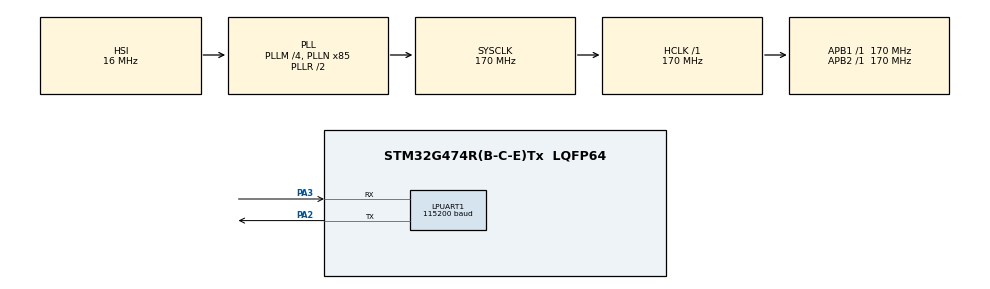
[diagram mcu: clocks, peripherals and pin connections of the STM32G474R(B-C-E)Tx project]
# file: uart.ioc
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Dma.LPUART1_RX.1.Direction=DMA_PERIPH_TO_MEMORY
Dma.LPUART1_RX.1.EventEnable=DISABLE
Dma.LPUART1_RX.1.Instance=DMA1_Channel2
Dma.LPUART1_RX.1.MemDataAlignment=DMA_MDATAALIGN_BYTE
Dma.LPUART1_RX.1.MemInc=DMA_MINC_ENABLE
Dma.LPUART1_RX.1.Mode=DMA_NORMAL
Dma.LPUART1_RX.1.PeriphDataAlignment=DMA_PDATAALIGN_BYTE
Dma.LPUART1_RX.1.PeriphInc=DMA_PINC_DISABLE
Dma.LPUART1_RX.1.Polarity=HAL_DMAMUX_REQ_GEN_RISING
Dma.LPUART1_RX.1.Priority=DMA_PRIORITY_LOW
Dma.LPUART1_RX.1.RequestNumber=1
Dma.LPUART1_RX.1.SignalID=NONE
Dma.LPUART1_RX.1.SyncEnable=DISABLE
Dma.LPUART1_RX.1.SyncPolarity=HAL_DMAMUX_SYNC_NO_EVENT
Dma.LPUART1_RX.1.SyncRequestNumber=1
Dma.LPUART1_RX.1.SyncSignalID=NONE
Dma.LPUART1_TX.0.Direction=DMA_MEMORY_TO_PERIPH
Dma.LPUART1_TX.0.EventEnable=DISABLE
Dma.LPUART1_TX.0.Instance=DMA1_Channel1
Dma.LPUART1_TX.0.MemDataAlignment=DMA_MDATAALIGN_BYTE
Dma.LPUART1_TX.0.MemInc=DMA_MINC_ENABLE
Dma.LPUART1_TX.0.Mode=DMA_NORMAL
Dma.LPUART1_TX.0.PeriphDataAlignment=DMA_PDATAALIGN_BYTE
Dma.LPUART1_TX.0.PeriphInc=DMA_PINC_DISABLE
Dma.LPUART1_TX.0.Polarity=HAL_DMAMUX_REQ_GEN_RISING
Dma.LPUART1_TX.0.Priority=DMA_PRIORITY_LOW
Dma.LPUART1_TX.0.RequestNumber=1
Dma.LPUART1_TX.0.SignalID=NONE
Dma.LPUART1_TX.0.SyncEnable=DISABLE
Dma.LPUART1_TX.0.SyncPolarity=HAL_DMAMUX_SYNC_NO_EVENT
Dma.LPUART1_TX.0.SyncRequestNumber=1
Dma.LPUART1_TX.0.SyncSignalID=NONE
Dma.Request0=LPUART1_TX
Dma.Request1=LPUART1_RX
LPUART1.BaudRate=115200
Mcu.Family=STM32G4
Mcu.Name=STM32G474R(B-C-E)Tx
Mcu.Package=LQFP64
NVIC.DMA1_Channel1_IRQn=true\:0\:0\:false\:false\:true\:false\:true\:true
NVIC.DMA1_Channel2_IRQn=true\:0\:0\:false\:false\:true\:false\:true\:true
NVIC.LPUART1_IRQn=true\:1\:0\:true\:false\:true\:true\:true\:true
NVIC.PriorityGroup=NVIC_PRIORITYGROUP_4
PA13.Mode=Serial_Wire
PA13.Signal=SYS_JTMS-SWDIO
PA14.Mode=Serial_Wire
PA14.Signal=SYS_JTCK-SWCLK
PA2.Mode=Asynchronous
PA2.Signal=LPUART1_TX
PA3.Mode=Asynchronous
PA3.Signal=LPUART1_RX
PF0-OSC_IN.Mode=HSE-External-Oscillator
PF0-OSC_IN.Signal=RCC_OSC_IN
PF1-OSC_OUT.Mode=HSE-External-Oscillator
PF1-OSC_OUT.Signal=RCC_OSC_OUT
ProjectManager.HeapSize=0x200
ProjectManager.StackSize=0x400
ProjectManager.TargetToolchain=CMake
RCC.ADC12Freq_Value=170000000
RCC.ADC345Freq_Value=170000000
RCC.AHBFreq_Value=170000000
RCC.APB1Freq_Value=170000000
RCC.APB1TimFreq_Value=170000000
RCC.APB2Freq_Value=170000000
RCC.APB2TimFreq_Value=170000000
RCC.CortexFreq_Value=170000000
RCC.EXTERNAL_CLOCK_VALUE=12288000
RCC.HCLKFreq_Value=170000000
RCC.HSE_VALUE=24000000
RCC.HSI48_VALUE=48000000
RCC.HSI_VALUE=16000000
RCC.LSE_VALUE=32768
RCC.PLLM=RCC_PLLM_DIV4
RCC.PLLN=85
RCC.SYSCLKFreq_VALUE=170000000
RCC.SYSCLKSource=RCC_SYSCLKSOURCE_PLLCLK
RCC.USBFreq_Value=170000000
RCC.VCOOutputFreq_Value=340000000
VP_SYS_VS_DBSignals.Mode=DisableDeadBatterySignals
board=custom

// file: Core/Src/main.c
/* USER CODE BEGIN Header */
/**
  ******************************************************************************
  * @file           : main.c
  * @brief          : Main program body
  ******************************************************************************
  * @attention
  *
  * Copyright (c) 2026 STMicroelectronics.
  * All rights reserved.
  *
  * This software is licensed under terms that can be found in the LICENSE file
  * in the root directory of this software component.
  * If no LICENSE file comes with this software, it is provided AS-IS.
  *
  ******************************************************************************
  */
/* USER CODE END Header */
#include "main.h"

/* USER CODE BEGIN Includes */
#include <stdio.h>
#include <string.h>
/* USER CODE END Includes */

/* USER CODE BEGIN PD */
#define UART_RX_BUFFER_SIZE          128U

/* USER CODE END PD */

UART_HandleTypeDef hlpuart1;
DMA_HandleTypeDef hdma_lpuart1_tx;
DMA_HandleTypeDef hdma_lpuart1_rx;

/* USER CODE BEGIN PV */
uint8_t received_data[UART_RX_BUFFER_SIZE];
uint8_t transmit_data[UART_RX_BUFFER_SIZE];
volatile uint16_t transmit_length;
/* USER CODE END PV */

void SystemClock_Config(void);
static void MX_GPIO_Init(void);
static void MX_DMA_Init(void);
static void MX_LPUART1_UART_Init(void);

/* USER CODE BEGIN 0 */
static void UART_StartReceiveToIdleDMA(void)
{
  if (HAL_UARTEx_ReceiveToIdle_DMA(&hlpuart1,
                                   received_data,
                                   UART_RX_BUFFER_SIZE) == HAL_OK)
  {
    __HAL_DMA_DISABLE_IT(hlpuart1.hdmarx, DMA_IT_HT);
  }
}

void HAL_UARTEx_RxEventCallback(UART_HandleTypeDef *huart, uint16_t Size)
{
  if ((huart == &hlpuart1) && (Size > 0U))
  {
    transmit_length = (Size <= UART_RX_BUFFER_SIZE) ? Size : UART_RX_BUFFER_SIZE;
    memcpy(transmit_data, received_data, transmit_length);

    if (HAL_UART_Transmit_DMA(&hlpuart1,
                              transmit_data,
                              transmit_length) != HAL_OK)
    {
      UART_StartReceiveToIdleDMA();
    }
  }
}

void HAL_UART_TxCpltCallback(UART_HandleTypeDef *huart)
{
  if (huart == &hlpuart1)
  {
    UART_StartReceiveToIdleDMA();
  }
}
/* USER CODE END 0 */

int main(void)
{

  /* MCU Configuration--------------------------------------------------------*/

  /* Reset of all peripherals, Initializes the Flash interface and the Systick. */
  HAL_Init();

  /* Configure the system clock */
  SystemClock_Config();

  /* Initialize all configured peripherals */
  MX_GPIO_Init();
  MX_DMA_Init();
  MX_LPUART1_UART_Init();
  /* USER CODE BEGIN 2 */
  printf("\r\nUART Printf Example: retarget the C library printf function to the UART\r\n");
  printf("** Test finished successfully. **\r\n");

  UART_StartReceiveToIdleDMA();

  /* USER CODE END 2 */

  /* Infinite loop */
  while (1)
  {

    /* USER CODE BEGIN 3 */
      //HAL_UART_Receive(&hlpuart1, received_data, 2, HAL_MAX_DELAY);

  }
  /* USER CODE END 3 */
}

void SystemClock_Config(void)
{
  RCC_OscInitTypeDef RCC_OscInitStruct = {0};
  RCC_ClkInitTypeDef RCC_ClkInitStruct = {0};

  /** Configure the main internal regulator output voltage
  */
  HAL_PWREx_ControlVoltageScaling(PWR_REGULATOR_VOLTAGE_SCALE1_BOOST);

  /** Initializes the RCC Oscillators according to the specified parameters
  * in the RCC_OscInitTypeDef structure.
  */
  RCC_OscInitStruct.OscillatorType = RCC_OSCILLATORTYPE_HSI;
  RCC_OscInitStruct.HSIState = RCC_HSI_ON;
  RCC_OscInitStruct.HSICalibrationValue = RCC_HSICALIBRATION_DEFAULT;
  RCC_OscInitStruct.PLL.PLLState = RCC_PLL_ON;
  RCC_OscInitStruct.PLL.PLLSource = RCC_PLLSOURCE_HSI;
  RCC_OscInitStruct.PLL.PLLM = RCC_PLLM_DIV4;
  RCC_OscInitStruct.PLL.PLLN = 85;
  RCC_OscInitStruct.PLL.PLLP = RCC_PLLP_DIV2;
  RCC_OscInitStruct.PLL.PLLQ = RCC_PLLQ_DIV2;
  RCC_OscInitStruct.PLL.PLLR = RCC_PLLR_DIV2;
  if (HAL_RCC_OscConfig(&RCC_OscInitStruct) != HAL_OK)
  {
    Error_Handler();
  }

  /** Initializes the CPU, AHB and APB buses clocks
  */
  RCC_ClkInitStruct.ClockType = RCC_CLOCKTYPE_HCLK|RCC_CLOCKTYPE_SYSCLK
                              |RCC_CLOCKTYPE_PCLK1|RCC_CLOCKTYPE_PCLK2;
  RCC_ClkInitStruct.SYSCLKSource = RCC_SYSCLKSOURCE_PLLCLK;
  RCC_ClkInitStruct.AHBCLKDivider = RCC_SYSCLK_DIV1;
  RCC_ClkInitStruct.APB1CLKDivider = RCC_HCLK_DIV1;
  RCC_ClkInitStruct.APB2CLKDivider = RCC_HCLK_DIV1;

  if (HAL_RCC_ClockConfig(&RCC_ClkInitStruct, FLASH_LATENCY_4) != HAL_OK)
  {
    Error_Handler();
  }
}

static void MX_LPUART1_UART_Init(void)
{

  hlpuart1.Instance = LPUART1;
  hlpuart1.Init.BaudRate = 115200;
  hlpuart1.Init.WordLength = UART_WORDLENGTH_8B;
  hlpuart1.Init.StopBits = UART_STOPBITS_1;
  hlpuart1.Init.Parity = UART_PARITY_NONE;
  hlpuart1.Init.Mode = UART_MODE_TX_RX;
  hlpuart1.Init.HwFlowCtl = UART_HWCONTROL_NONE;
  hlpuart1.Init.OneBitSampling = UART_ONE_BIT_SAMPLE_DISABLE;
  hlpuart1.Init.ClockPrescaler = UART_PRESCALER_DIV1;
  hlpuart1.AdvancedInit.AdvFeatureInit = UART_ADVFEATURE_NO_INIT;
  if (HAL_UART_Init(&hlpuart1) != HAL_OK)
  {
    Error_Handler();
  }
  if (HAL_UARTEx_SetTxFifoThreshold(&hlpuart1, UART_TXFIFO_THRESHOLD_1_8) != HAL_OK)
  {
    Error_Handler();
  }
  if (HAL_UARTEx_SetRxFifoThreshold(&hlpuart1, UART_RXFIFO_THRESHOLD_1_8) != HAL_OK)
  {
    Error_Handler();
  }
  if (HAL_UARTEx_DisableFifoMode(&hlpuart1) != HAL_OK)
  {
    Error_Handler();
  }

}

static void MX_DMA_Init(void)
{

  /* DMA controller clock enable */
  __HAL_RCC_DMAMUX1_CLK_ENABLE();
  __HAL_RCC_DMA1_CLK_ENABLE();

  /* DMA interrupt init */
  /* DMA1_Channel1_IRQn interrupt configuration */
  HAL_NVIC_SetPriority(DMA1_Channel1_IRQn, 0, 0);
  HAL_NVIC_EnableIRQ(DMA1_Channel1_IRQn);
  /* DMA1_Channel2_IRQn interrupt configuration */
  HAL_NVIC_SetPriority(DMA1_Channel2_IRQn, 0, 0);
  HAL_NVIC_EnableIRQ(DMA1_Channel2_IRQn);

}

static void MX_GPIO_Init(void)
{

  /* GPIO Ports Clock Enable */
  __HAL_RCC_GPIOF_CLK_ENABLE();
  __HAL_RCC_GPIOA_CLK_ENABLE();

}

/* USER CODE BEGIN 4 */

int __io_putchar(int ch)
{
  HAL_UART_Transmit(&hlpuart1, (uint8_t *)&ch, 1, 0xFFFF);
  return ch;
}

int fputc(int ch, FILE *f)
{
  (void)f;
  return __io_putchar(ch);
}
/* USER CODE END 4 */

void Error_Handler(void)
{
  __disable_irq();
  while (1)
  {
  }
}
